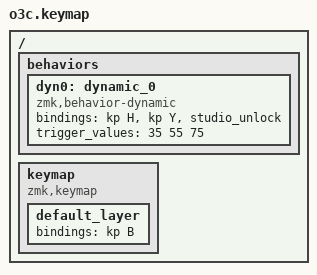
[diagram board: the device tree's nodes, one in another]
/*
 * Copyright (c) 2020 The ZMK Contributors
 *
 * SPDX-License-Identifier: MIT
 */

#include <behaviors.dtsi>
#include <dt-bindings/zmk/keys.h>

/ {
    behaviors {
        dyn0: dynamic_0 {
            compatible = "zmk,behavior-dynamic";
            #binding-cells = <2>;
            bindings = <&kp H &kp Y &studio_unlock>;
            trigger_values = <35 55 75>;
        };
    };

    keymap {
        compatible = "zmk,keymap";

        default_layer {
            bindings = <
            &kp B
            >;
        };
    };
};
